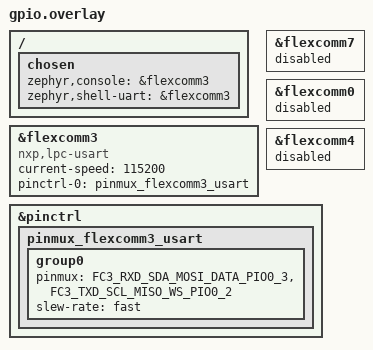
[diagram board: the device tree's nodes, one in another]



/* Simple overlay - UART console only, no I2C conflicts */

/* UART Console - flexcomm3 */
&flexcomm3 {
    compatible = "nxp,lpc-usart";
    status = "okay";
    current-speed = <115200>;
    pinctrl-0 = <&pinmux_flexcomm3_usart>;
    pinctrl-names = "default";
};

/* Explicitly disable I2C to prevent conflicts */
&flexcomm7 {
    status = "disabled";
};

&flexcomm0 {
    status = "disabled";
};

&flexcomm4 {
    status = "disabled";
};

/* Pin multiplexing configuration */
&pinctrl {
    /* UART pins for console */
    pinmux_flexcomm3_usart: pinmux_flexcomm3_usart {
        group0 {
            pinmux = <FC3_RXD_SDA_MOSI_DATA_PIO0_3>,
                     <FC3_TXD_SCL_MISO_WS_PIO0_2>;
            slew-rate = "fast";
        };
    };
};

/* Chosen nodes */
/ {
    chosen {
        zephyr,console = &flexcomm3;
        zephyr,shell-uart = &flexcomm3;
    };
};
